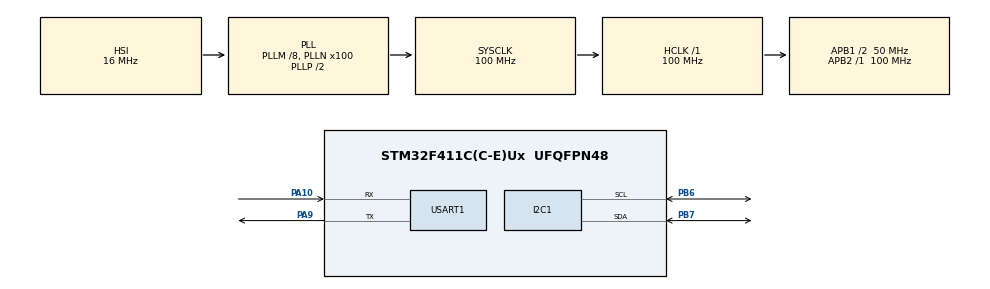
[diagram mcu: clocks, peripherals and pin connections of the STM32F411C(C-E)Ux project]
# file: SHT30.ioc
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I2C1.I2C_Mode=I2C_Fast
Mcu.Family=STM32F4
Mcu.Name=STM32F411C(C-E)Ux
Mcu.Package=UFQFPN48
NVIC.PriorityGroup=NVIC_PRIORITYGROUP_4
PA10.Mode=Asynchronous
PA10.Signal=USART1_RX
PA13.Mode=Serial_Wire
PA13.Signal=SYS_JTMS-SWDIO
PA14.Mode=Serial_Wire
PA14.Signal=SYS_JTCK-SWCLK
PA9.Mode=Asynchronous
PA9.Signal=USART1_TX
PB6.Mode=I2C
PB6.Signal=I2C1_SCL
PB7.Mode=I2C
PB7.Signal=I2C1_SDA
PH0\ -\ OSC_IN.Mode=HSE-External-Oscillator
PH0\ -\ OSC_IN.Signal=RCC_OSC_IN
PH1\ -\ OSC_OUT.Mode=HSE-External-Oscillator
PH1\ -\ OSC_OUT.Signal=RCC_OSC_OUT
ProjectManager.HeapSize=0x200
ProjectManager.StackSize=0x400
ProjectManager.TargetToolchain=STM32CubeIDE
RCC.48MHZClocksFreq_Value=50000000
RCC.AHBFreq_Value=100000000
RCC.APB1CLKDivider=RCC_HCLK_DIV2
RCC.APB1Freq_Value=50000000
RCC.APB1TimFreq_Value=100000000
RCC.APB2Freq_Value=100000000
RCC.APB2TimFreq_Value=100000000
RCC.CortexFreq_Value=100000000
RCC.HCLKFreq_Value=100000000
RCC.HSE_VALUE=25000000
RCC.HSI_VALUE=16000000
RCC.LSE_VALUE=32768
RCC.PLLM=8
RCC.PLLN=100
RCC.SYSCLKFreq_VALUE=100000000
RCC.SYSCLKSource=RCC_SYSCLKSOURCE_PLLCLK
RCC.VCOOutputFreq_Value=200000000
USART1.VirtualMode=VM_ASYNC
board=custom

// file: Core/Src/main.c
/* USER CODE BEGIN Header */
/**
  ******************************************************************************
  * @file           : main.c
  * @brief          : Main program body
  ******************************************************************************
  * @attention
  *
  * Copyright (c) 2026 STMicroelectronics.
  * All rights reserved.
  *
  * This software is licensed under terms that can be found in the LICENSE file
  * in the root directory of this software component.
  * If no LICENSE file comes with this software, it is provided AS-IS.
  *
  ******************************************************************************
  */
/* USER CODE END Header */
#include "main.h"

/* USER CODE BEGIN Includes */
#include "stdio.h"
/* USER CODE END Includes */

/* USER CODE BEGIN PD */
#define SHT30_ADDR (0x44 << 1)
/* USER CODE END PD */

I2C_HandleTypeDef hi2c1;

UART_HandleTypeDef huart1;

/* USER CODE BEGIN PV */

uint8_t sht30_cmd[2] = {0x24, 0x00};
uint8_t sht30_data[6];
char bufftemp[10], buffhumid[10], buffer[20];
float temperature, humidity;
/* USER CODE END PV */

void SystemClock_Config(void);
static void MX_GPIO_Init(void);
static void MX_I2C1_Init(void);
static void MX_USART1_UART_Init(void);
/* USER CODE BEGIN PFP */
HAL_StatusTypeDef SHT30_Read(float*, float*);
/* USER CODE END PFP */

int main(void)
{

  /* MCU Configuration--------------------------------------------------------*/

  /* Reset of all peripherals, Initializes the Flash interface and the Systick. */
  HAL_Init();

  /* Configure the system clock */
  SystemClock_Config();

  /* Initialize all configured peripherals */
  MX_GPIO_Init();
  MX_I2C1_Init();
  MX_USART1_UART_Init();

  /* Infinite loop */
  while (1)
  {
	  if (SHT30_Read(&temperature, &humidity) == HAL_OK)
	  	      {
	  		  //SH1106_Write("Temp: ", &Font_7x10, 5, 5);
	  		  sprintf(buffer, "Temp: %.2f Humid: %.2f \r\n", temperature, humidity);
	  		  HAL_UART_Transmit(&huart1, (uint8_t*)buffer, strlen(buffer), HAL_MAX_DELAY);
//	  		  //SH1106_Write(bufftemp, &Font_7x10, 47, 5);
//	  		  sprintf(buffhumid, "Humid: %.2f\r\n", humidity);
//	  		  HAL_UART_Transmit(&huart1, (uint8_t*)buffhumid, 50, HAL_MAX_DELAY);
	  		  //		  sprintf(buffertemp, "Temp: %.2f", temperature);
	  //		  HAL_UART_Transmit(&huart1, (uint8_t*)buffertemp, 50, HAL_MAX_DELAY);
	  //		  HAL_Delay(10);
	  //		  sprintf(bufferhumid, "Humid: %.2f", humidity);
	  //		  HAL_UART_Transmit(&huart1, (uint8_t*)bufferhumid, 50, HAL_MAX_DELAY);
	  //		  SH1106_GotoXY(10,5);
	  //		  SH1106_Puts("Temp: ", &Font_7x10, 1);
	  //		  SH1106_GotoXY(52,5);
	  //		  sprintf(bufftemp, "%.2f", temperature);
	  //		  SH1106_Puts(bufftemp, &Font_7x10, 1);
	  //		  SH1106_GotoXY(10,15);
	  //		  SH1106_Puts("Humid: ", &Font_7x10, 1);
	  //		  sprintf(buffhumid, "%.2f", humidity);
	  //		  SH1106_GotoXY(59,15);
	  //		  SH1106_Puts(buffhumid, &Font_7x10, 1);
	  //		  SH1106_UpdateScreen();
	  	      }
	  	      HAL_Delay(1000);

  }
}

void SystemClock_Config(void)
{
  RCC_OscInitTypeDef RCC_OscInitStruct = {0};
  RCC_ClkInitTypeDef RCC_ClkInitStruct = {0};

  /** Configure the main internal regulator output voltage
  */
  __HAL_RCC_PWR_CLK_ENABLE();
  __HAL_PWR_VOLTAGESCALING_CONFIG(PWR_REGULATOR_VOLTAGE_SCALE1);

  /** Initializes the RCC Oscillators according to the specified parameters
  * in the RCC_OscInitTypeDef structure.
  */
  RCC_OscInitStruct.OscillatorType = RCC_OSCILLATORTYPE_HSI;
  RCC_OscInitStruct.HSIState = RCC_HSI_ON;
  RCC_OscInitStruct.HSICalibrationValue = RCC_HSICALIBRATION_DEFAULT;
  RCC_OscInitStruct.PLL.PLLState = RCC_PLL_ON;
  RCC_OscInitStruct.PLL.PLLSource = RCC_PLLSOURCE_HSI;
  RCC_OscInitStruct.PLL.PLLM = 8;
  RCC_OscInitStruct.PLL.PLLN = 100;
  RCC_OscInitStruct.PLL.PLLP = RCC_PLLP_DIV2;
  RCC_OscInitStruct.PLL.PLLQ = 4;
  if (HAL_RCC_OscConfig(&RCC_OscInitStruct) != HAL_OK)
  {
    Error_Handler();
  }

  /** Initializes the CPU, AHB and APB buses clocks
  */
  RCC_ClkInitStruct.ClockType = RCC_CLOCKTYPE_HCLK|RCC_CLOCKTYPE_SYSCLK
                              |RCC_CLOCKTYPE_PCLK1|RCC_CLOCKTYPE_PCLK2;
  RCC_ClkInitStruct.SYSCLKSource = RCC_SYSCLKSOURCE_PLLCLK;
  RCC_ClkInitStruct.AHBCLKDivider = RCC_SYSCLK_DIV1;
  RCC_ClkInitStruct.APB1CLKDivider = RCC_HCLK_DIV2;
  RCC_ClkInitStruct.APB2CLKDivider = RCC_HCLK_DIV1;

  if (HAL_RCC_ClockConfig(&RCC_ClkInitStruct, FLASH_LATENCY_3) != HAL_OK)
  {
    Error_Handler();
  }
}

HAL_StatusTypeDef SHT30_Read(float *temp, float *humi)
{
   // Gửi lệnh đo
   if (HAL_I2C_Master_Transmit(&hi2c1, SHT30_ADDR, sht30_cmd, 2, 100) != HAL_OK)
       return HAL_ERROR;
   HAL_Delay(20); // chờ đo
   // Đọc 6 byte
   if (HAL_I2C_Master_Receive(&hi2c1, SHT30_ADDR, sht30_data, 6, 100) != HAL_OK)
       return HAL_ERROR;
   // Ghép dữ liệu
   uint16_t rawTemp = (sht30_data[0] << 8) | sht30_data[1];
   uint16_t rawHumi = (sht30_data[3] << 8) | sht30_data[4];
   // Công thức chuyển đổi (theo datasheet)
   *temp = -45 + 175 * ((float)rawTemp / 65535.0);
   *humi = 100 * ((float)rawHumi / 65535.0);
   return HAL_OK;
}

static void MX_I2C1_Init(void)
{

  hi2c1.Instance = I2C1;
  hi2c1.Init.ClockSpeed = 400000;
  hi2c1.Init.DutyCycle = I2C_DUTYCYCLE_2;
  hi2c1.Init.OwnAddress1 = 0;
  hi2c1.Init.AddressingMode = I2C_ADDRESSINGMODE_7BIT;
  hi2c1.Init.DualAddressMode = I2C_DUALADDRESS_DISABLE;
  hi2c1.Init.OwnAddress2 = 0;
  hi2c1.Init.GeneralCallMode = I2C_GENERALCALL_DISABLE;
  hi2c1.Init.NoStretchMode = I2C_NOSTRETCH_DISABLE;
  if (HAL_I2C_Init(&hi2c1) != HAL_OK)
  {
    Error_Handler();
  }

}

static void MX_USART1_UART_Init(void)
{

  huart1.Instance = USART1;
  huart1.Init.BaudRate = 115200;
  huart1.Init.WordLength = UART_WORDLENGTH_8B;
  huart1.Init.StopBits = UART_STOPBITS_1;
  huart1.Init.Parity = UART_PARITY_NONE;
  huart1.Init.Mode = UART_MODE_TX_RX;
  huart1.Init.HwFlowCtl = UART_HWCONTROL_NONE;
  huart1.Init.OverSampling = UART_OVERSAMPLING_16;
  if (HAL_UART_Init(&huart1) != HAL_OK)
  {
    Error_Handler();
  }

}

static void MX_GPIO_Init(void)
{

  /* GPIO Ports Clock Enable */
  __HAL_RCC_GPIOH_CLK_ENABLE();
  __HAL_RCC_GPIOA_CLK_ENABLE();
  __HAL_RCC_GPIOB_CLK_ENABLE();

}

void Error_Handler(void)
{
  __disable_irq();
  while (1)
  {
  }
}
